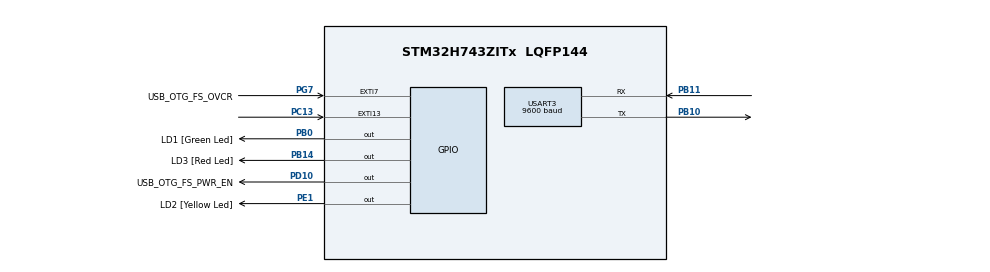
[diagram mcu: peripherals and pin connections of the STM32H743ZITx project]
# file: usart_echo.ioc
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Mcu.Family=STM32H7
Mcu.Name=STM32H743ZITx
Mcu.Package=LQFP144
NVIC.EXTI15_10_IRQn=true\:0\:0\:false\:false\:true\:true\:true\:true
NVIC.PriorityGroup=NVIC_PRIORITYGROUP_4
NVIC.USART3_IRQn=true\:0\:0\:false\:false\:true\:true\:true\:true
PB0.GPIO_Label=LD1 [Green Led]
PB0.Signal=GPIO_Output
PB10.Mode=Asynchronous
PB10.Signal=USART3_TX
PB11.Mode=Asynchronous
PB11.Signal=USART3_RX
PB14.GPIO_Label=LD3 [Red Led]
PB14.Signal=GPIO_Output
PC13.Signal=GPXTI13
PC14-OSC32_IN\ (OSC32_IN).Mode=LSE-External-Oscillator
PC14-OSC32_IN\ (OSC32_IN).Signal=RCC_OSC32_IN
PC15-OSC32_OUT\ (OSC32_OUT).Mode=LSE-External-Oscillator
PC15-OSC32_OUT\ (OSC32_OUT).Signal=RCC_OSC32_OUT
PD10.GPIO_Label=USB_OTG_FS_PWR_EN
PD10.Signal=GPIO_Output
PE1.GPIO_Label=LD2 [Yellow Led]
PE1.Signal=GPIO_Output
PG7.GPIO_Label=USB_OTG_FS_OVCR
PG7.Signal=GPXTI7
PH0-OSC_IN\ (PH0).Mode=HSE-External-Clock-Source
PH0-OSC_IN\ (PH0).Signal=RCC_OSC_IN
ProjectManager.HeapSize=0x200
ProjectManager.StackSize=0x400
ProjectManager.TargetToolchain=STM32CubeIDE
RCC.ADCFreq_Value=16125000
RCC.APB1Freq_Value=64000000
RCC.APB2Freq_Value=64000000
RCC.APB3Freq_Value=64000000
RCC.APB4Freq_Value=64000000
RCC.CortexFreq_Value=64000000
RCC.DIVM1=1
RCC.DIVN1=24
RCC.DIVQ1=4
RCC.HCLKFreq_Value=64000000
RCC.HSE_VALUE=8000000
RCC.PLLFRACN=0
RCC.PLLSourceVirtual=RCC_PLLSOURCE_HSE
RCC.PWR_Regulator_Voltage_Scale=PWR_REGULATOR_VOLTAGE_SCALE2
RCC.SYSCLKFreq_VALUE=64000000
RCC.USBFreq_Value=48000000
USART3.BaudRate=9600
USART3.VirtualMode-Asynchronous=VM_ASYNC
VP_MEMORYMAP_VS_MEMORYMAP.Mode=CurAppReg
board=NUCLEO-H743ZI2

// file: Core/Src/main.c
/* USER CODE BEGIN Header */
/**
  ******************************************************************************
  * @file           : main.c
  * @brief          : Main program body
  ******************************************************************************
  * @attention
  *
  * Copyright (c) 2025 STMicroelectronics.
  * All rights reserved.
  *
  * This software is licensed under terms that can be found in the LICENSE file
  * in the root directory of this software component.
  * If no LICENSE file comes with this software, it is provided AS-IS.
  *
  ******************************************************************************
  */
/* USER CODE END Header */
#include "main.h"

UART_HandleTypeDef huart3;

void SystemClock_Config(void);
static void MX_GPIO_Init(void);
static void MX_USART3_UART_Init(void);

int main(void)
{

  /* MCU Configuration--------------------------------------------------------*/

  /* Reset of all peripherals, Initializes the Flash interface and the Systick. */
  HAL_Init();

  /* Configure the system clock */
  SystemClock_Config();

  /* Initialize all configured peripherals */
  MX_GPIO_Init();
  MX_USART3_UART_Init();
  /* USER CODE BEGIN 2 */
  USART3->CR1 |= USART_CR1_TE;
  USART3->CR1 |= USART_CR1_RE;
  USART3->CR1 |= USART_CR1_TCIE;
  USART3->CR1 |= USART_CR1_RXNEIE;
  USART3->CR1 |=  USART_CR1_UE;

  /* USER CODE END 2 */

  /* Infinite loop */
  while (1)
  {

  }
}

void SystemClock_Config(void)
{
  RCC_OscInitTypeDef RCC_OscInitStruct = {0};
  RCC_ClkInitTypeDef RCC_ClkInitStruct = {0};

  /** Supply configuration update enable
  */
  HAL_PWREx_ConfigSupply(PWR_LDO_SUPPLY);

  /** Configure the main internal regulator output voltage
  */
  __HAL_PWR_VOLTAGESCALING_CONFIG(PWR_REGULATOR_VOLTAGE_SCALE2);

  while(!__HAL_PWR_GET_FLAG(PWR_FLAG_VOSRDY)) {}

  /** Initializes the RCC Oscillators according to the specified parameters
  * in the RCC_OscInitTypeDef structure.
  */
  RCC_OscInitStruct.OscillatorType = RCC_OSCILLATORTYPE_HSI;
  RCC_OscInitStruct.HSIState = RCC_HSI_DIV1;
  RCC_OscInitStruct.HSICalibrationValue = RCC_HSICALIBRATION_DEFAULT;
  RCC_OscInitStruct.PLL.PLLState = RCC_PLL_NONE;
  if (HAL_RCC_OscConfig(&RCC_OscInitStruct) != HAL_OK)
  {
    Error_Handler();
  }

  /** Initializes the CPU, AHB and APB buses clocks
  */
  RCC_ClkInitStruct.ClockType = RCC_CLOCKTYPE_HCLK|RCC_CLOCKTYPE_SYSCLK
                              |RCC_CLOCKTYPE_PCLK1|RCC_CLOCKTYPE_PCLK2
                              |RCC_CLOCKTYPE_D3PCLK1|RCC_CLOCKTYPE_D1PCLK1;
  RCC_ClkInitStruct.SYSCLKSource = RCC_SYSCLKSOURCE_HSI;
  RCC_ClkInitStruct.SYSCLKDivider = RCC_SYSCLK_DIV1;
  RCC_ClkInitStruct.AHBCLKDivider = RCC_HCLK_DIV1;
  RCC_ClkInitStruct.APB3CLKDivider = RCC_APB3_DIV1;
  RCC_ClkInitStruct.APB1CLKDivider = RCC_APB1_DIV1;
  RCC_ClkInitStruct.APB2CLKDivider = RCC_APB2_DIV1;
  RCC_ClkInitStruct.APB4CLKDivider = RCC_APB4_DIV1;

  if (HAL_RCC_ClockConfig(&RCC_ClkInitStruct, FLASH_LATENCY_1) != HAL_OK)
  {
    Error_Handler();
  }
}

static void MX_USART3_UART_Init(void)
{

  huart3.Instance = USART3;
  huart3.Init.BaudRate = 9600;
  huart3.Init.WordLength = UART_WORDLENGTH_8B;
  huart3.Init.StopBits = UART_STOPBITS_1;
  huart3.Init.Parity = UART_PARITY_NONE;
  huart3.Init.Mode = UART_MODE_TX_RX;
  huart3.Init.HwFlowCtl = UART_HWCONTROL_NONE;
  huart3.Init.OverSampling = UART_OVERSAMPLING_16;
  huart3.Init.OneBitSampling = UART_ONE_BIT_SAMPLE_DISABLE;
  huart3.Init.ClockPrescaler = UART_PRESCALER_DIV1;
  huart3.AdvancedInit.AdvFeatureInit = UART_ADVFEATURE_NO_INIT;
  if (HAL_UART_Init(&huart3) != HAL_OK)
  {
    Error_Handler();
  }
  if (HAL_UARTEx_SetTxFifoThreshold(&huart3, UART_TXFIFO_THRESHOLD_1_8) != HAL_OK)
  {
    Error_Handler();
  }
  if (HAL_UARTEx_SetRxFifoThreshold(&huart3, UART_RXFIFO_THRESHOLD_1_8) != HAL_OK)
  {
    Error_Handler();
  }
  if (HAL_UARTEx_DisableFifoMode(&huart3) != HAL_OK)
  {
    Error_Handler();
  }

}

static void MX_GPIO_Init(void)
{
  GPIO_InitTypeDef GPIO_InitStruct = {0};

  /* GPIO Ports Clock Enable */
  __HAL_RCC_GPIOC_CLK_ENABLE();
  __HAL_RCC_GPIOH_CLK_ENABLE();
  __HAL_RCC_GPIOB_CLK_ENABLE();
  __HAL_RCC_GPIOD_CLK_ENABLE();
  __HAL_RCC_GPIOG_CLK_ENABLE();
  __HAL_RCC_GPIOE_CLK_ENABLE();

  /*Configure GPIO pin Output Level */
  HAL_GPIO_WritePin(GPIOB, LD1_Pin|LD3_Pin, GPIO_PIN_RESET);

  /*Configure GPIO pin Output Level */
  HAL_GPIO_WritePin(USB_OTG_FS_PWR_EN_GPIO_Port, USB_OTG_FS_PWR_EN_Pin, GPIO_PIN_RESET);

  /*Configure GPIO pin Output Level */
  HAL_GPIO_WritePin(LD2_GPIO_Port, LD2_Pin, GPIO_PIN_RESET);

  /*Configure GPIO pin : PC13 */
  GPIO_InitStruct.Pin = GPIO_PIN_13;
  GPIO_InitStruct.Mode = GPIO_MODE_IT_RISING;
  GPIO_InitStruct.Pull = GPIO_NOPULL;
  HAL_GPIO_Init(GPIOC, &GPIO_InitStruct);

  /*Configure GPIO pins : LD1_Pin LD3_Pin */
  GPIO_InitStruct.Pin = LD1_Pin|LD3_Pin;
  GPIO_InitStruct.Mode = GPIO_MODE_OUTPUT_PP;
  GPIO_InitStruct.Pull = GPIO_NOPULL;
  GPIO_InitStruct.Speed = GPIO_SPEED_FREQ_LOW;
  HAL_GPIO_Init(GPIOB, &GPIO_InitStruct);

  /*Configure GPIO pin : USB_OTG_FS_PWR_EN_Pin */
  GPIO_InitStruct.Pin = USB_OTG_FS_PWR_EN_Pin;
  GPIO_InitStruct.Mode = GPIO_MODE_OUTPUT_PP;
  GPIO_InitStruct.Pull = GPIO_NOPULL;
  GPIO_InitStruct.Speed = GPIO_SPEED_FREQ_LOW;
  HAL_GPIO_Init(USB_OTG_FS_PWR_EN_GPIO_Port, &GPIO_InitStruct);

  /*Configure GPIO pin : USB_OTG_FS_OVCR_Pin */
  GPIO_InitStruct.Pin = USB_OTG_FS_OVCR_Pin;
  GPIO_InitStruct.Mode = GPIO_MODE_IT_RISING;
  GPIO_InitStruct.Pull = GPIO_NOPULL;
  HAL_GPIO_Init(USB_OTG_FS_OVCR_GPIO_Port, &GPIO_InitStruct);

  /*Configure GPIO pin : LD2_Pin */
  GPIO_InitStruct.Pin = LD2_Pin;
  GPIO_InitStruct.Mode = GPIO_MODE_OUTPUT_PP;
  GPIO_InitStruct.Pull = GPIO_NOPULL;
  GPIO_InitStruct.Speed = GPIO_SPEED_FREQ_LOW;
  HAL_GPIO_Init(LD2_GPIO_Port, &GPIO_InitStruct);

  /* EXTI interrupt init*/
  HAL_NVIC_SetPriority(EXTI15_10_IRQn, 0, 0);
  HAL_NVIC_EnableIRQ(EXTI15_10_IRQn);

}

void Error_Handler(void)
{
  __disable_irq();
  while (1)
  {
  }
}
